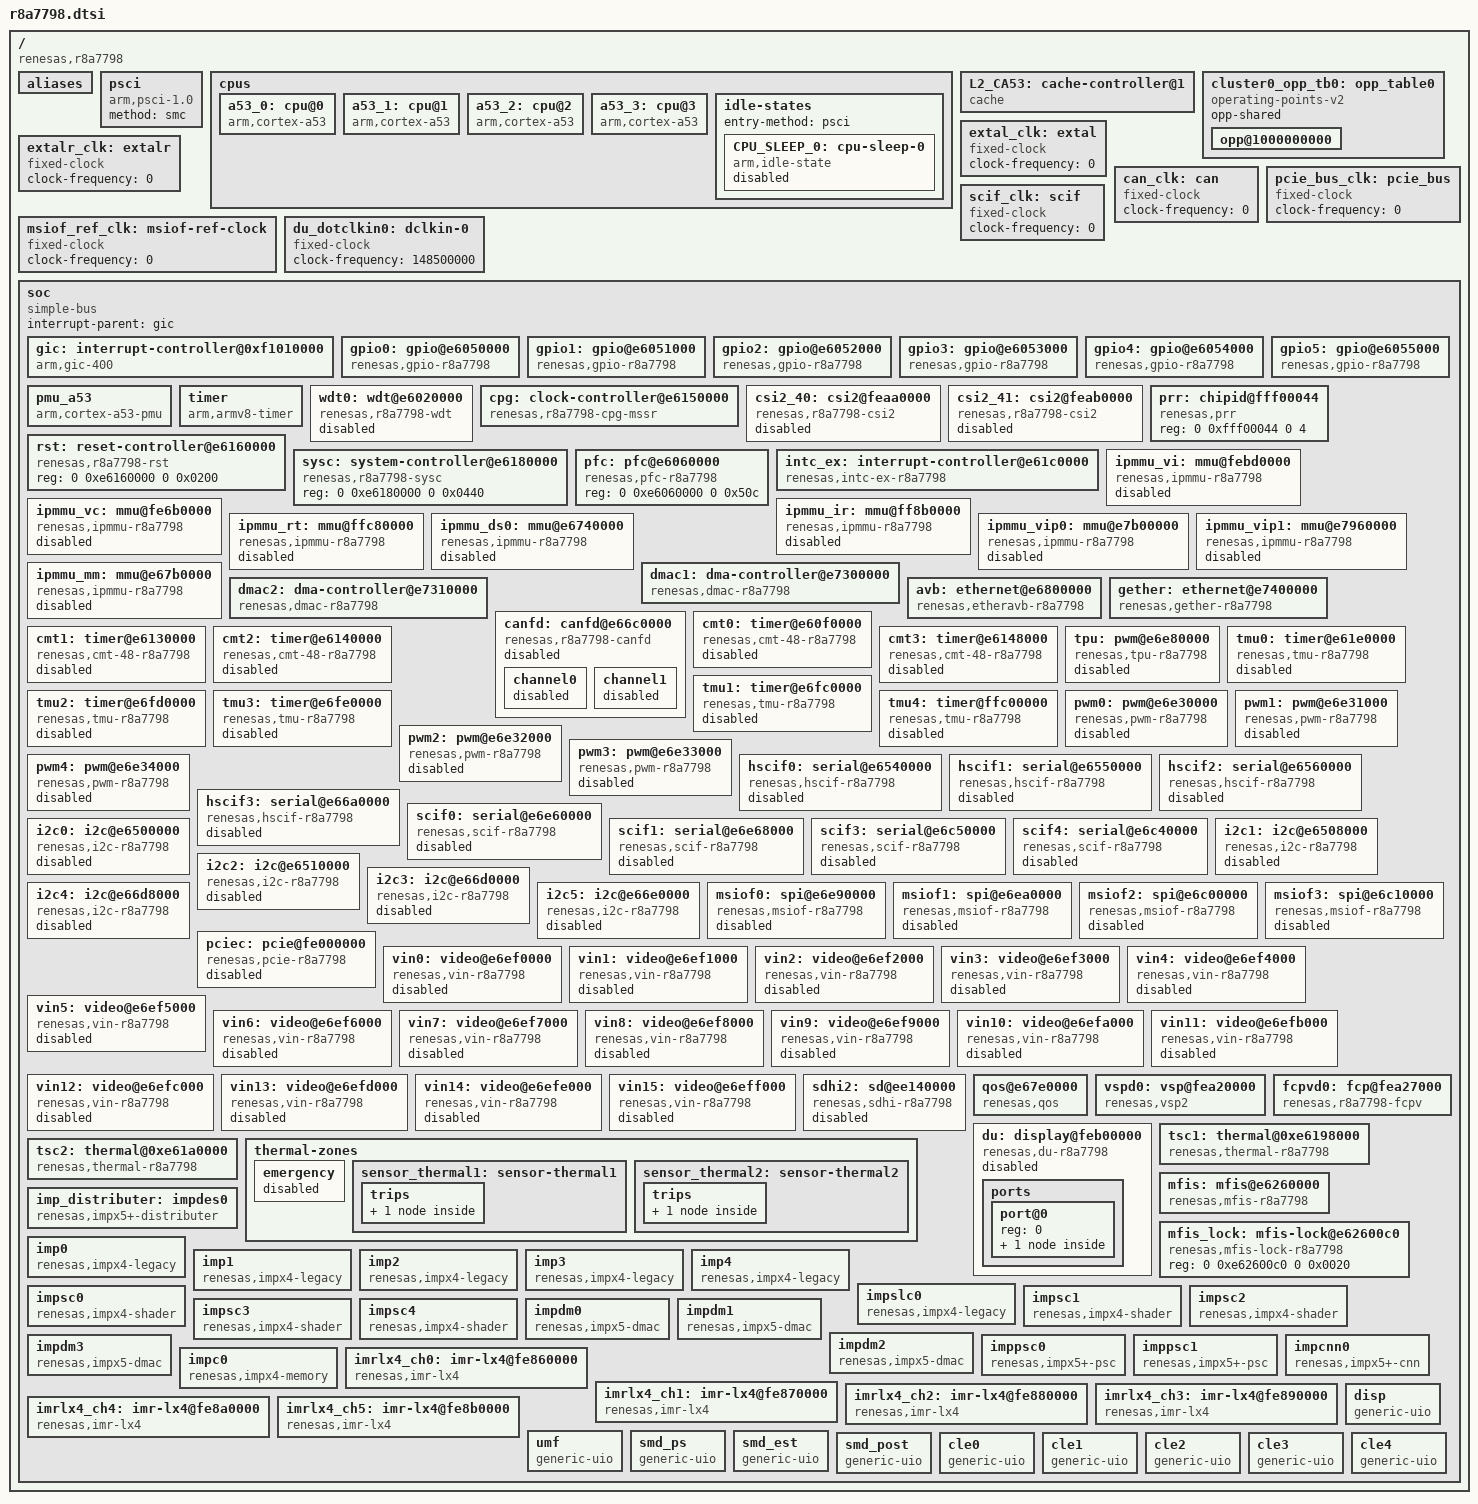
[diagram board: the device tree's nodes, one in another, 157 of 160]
/*
 * Device Tree Source for the r8a7798 SoC
 *
 * Copyright (C) 2018 Renesas Electronics Corp.
 * Copyright (C) 2018 Cogent Embedded, Inc.
 *
 * This file is licensed under the terms of the GNU General Public License
 * version 2.  This program is licensed "as is" without any warranty of any
 * kind, whether express or implied.
 */

#include <dt-bindings/clock/r8a7798-cpg-mssr.h>
#include <dt-bindings/interrupt-controller/arm-gic.h>
#include <dt-bindings/power/r8a7798-sysc.h>

/ {
	compatible = "renesas,r8a7798";
	#address-cells = <2>;
	#size-cells = <2>;

	aliases {
		csi2_40 = &csi2_40;
		csi2_41 = &csi2_41;
		i2c0 = &i2c0;
		i2c1 = &i2c1;
		i2c2 = &i2c2;
		i2c3 = &i2c3;
		i2c4 = &i2c4;
		i2c5 = &i2c5;
		spi1 = &msiof0;
		spi2 = &msiof1;
		spi3 = &msiof2;
		spi4 = &msiof3;
		vin0 = &vin0;
		vin1 = &vin1;
		vin2 = &vin2;
		vin3 = &vin3;
		vin4 = &vin4;
		vin5 = &vin5;
		vin6 = &vin6;
		vin7 = &vin7;
		vin8 = &vin8;
		vin9 = &vin9;
		vin10 = &vin10;
		vin11 = &vin11;
		vin12 = &vin12;
		vin13 = &vin13;
		vin14 = &vin14;
		vin15 = &vin15;
		tsc0 = &tsc1;
		tsc1 = &tsc2;
	};

	psci {
		compatible = "arm,psci-1.0";
		method = "smc";
	};

	cpus {
		#address-cells = <1>;
		#size-cells = <0>;

		a53_0: cpu@0 {
			compatible = "arm,cortex-a53", "arm,armv8";
			reg = <0x0>;
			device_type = "cpu";
			power-domains = <&sysc R8A7798_PD_CA53_CPU0>;
			next-level-cache = <&L2_CA53>;
			enable-method = "psci";
			cpu-idle-states = <&CPU_SLEEP_0>;
			#cooling-cells = <2>;
			dynamic-power-coefficient = <277>;
			cooling-min-level = <0>;
			cooling-max-level = <2>;
			clocks =<&cpg CPG_CORE R8A7798_CLK_Z2>;
			operating-points-v2 = <&cluster0_opp_tb0>;
			/*cpu-supply = <&vdd_dvfs>;*/
		};

		a53_1: cpu@1 {
			compatible = "arm,cortex-a53","arm,armv8";
			reg = <0x1>;
			device_type = "cpu";
			power-domains = <&sysc R8A7798_PD_CA53_CPU1>;
			next-level-cache = <&L2_CA53>;
			enable-method = "psci";
			cpu-idle-states = <&CPU_SLEEP_0>;
			operating-points-v2 = <&cluster0_opp_tb0>;
		};

		a53_2: cpu@2 {
			compatible = "arm,cortex-a53","arm,armv8";
			reg = <0x2>;
			device_type = "cpu";
			power-domains = <&sysc R8A7798_PD_CA53_CPU2>;
			next-level-cache = <&L2_CA53>;
			enable-method = "psci";
			cpu-idle-states = <&CPU_SLEEP_0>;
			operating-points-v2 = <&cluster0_opp_tb0>;
		};

		a53_3: cpu@3 {
			compatible = "arm,cortex-a53","arm,armv8";
			reg = <0x3>;
			device_type = "cpu";
			power-domains = <&sysc R8A7798_PD_CA53_CPU3>;
			next-level-cache = <&L2_CA53>;
			enable-method = "psci";
			cpu-idle-states = <&CPU_SLEEP_0>;
			operating-points-v2 = <&cluster0_opp_tb0>;
		};

		idle-states {
			entry-method = "psci";

			CPU_SLEEP_0: cpu-sleep-0 {
				compatible = "arm,idle-state";
				arm,psci-suspend-param = <0x0010000>;
				local-timer-stop;
				entry-latency-us = <639>;
				exit-latency-us = <680>;
				min-residency-us = <1088>;
				status = "disabled";
			};
		};
	};

	L2_CA53: cache-controller@1 {
		compatible = "cache";
		power-domains = <&sysc R8A7798_PD_CA53_SCU>;
		cache-unified;
		cache-level = <2>;
	};

	cluster0_opp_tb0: opp_table0 {
		compatible = "operating-points-v2";
		opp-shared;

		opp@1000000000 {
			opp-hz = /bits/ 64 <1000000000>;
			opp-microvolt = <850000>; /* TBD; section 87.2 */
			clock-latency-ns = <300000>;
		};
	};

	extal_clk: extal {
		compatible = "fixed-clock";
		#clock-cells = <0>;
		/* This value must be overridden by the board */
		clock-frequency = <0>;
	};

	extalr_clk: extalr {
		compatible = "fixed-clock";
		#clock-cells = <0>;
		/* This value must be overridden by the board */
		clock-frequency = <0>;
	};

	can_clk: can {
		compatible = "fixed-clock";
		#clock-cells = <0>;
		clock-frequency = <0>;
	};

	/* MSIOF reference clock - to be overridden by boards that provide it */
	msiof_ref_clk: msiof-ref-clock {
		compatible = "fixed-clock";
		#clock-cells = <0>;
		clock-frequency = <0>;
	};

	/* External PCIe clock - can be overridden by the board */
	pcie_bus_clk: pcie_bus {
		compatible = "fixed-clock";
		#clock-cells = <0>;
		clock-frequency = <0>;
	};

	/* External SCIF clock - to be overridden by boards that provide it */
	scif_clk: scif {
		compatible = "fixed-clock";
		#clock-cells = <0>;
		clock-frequency = <0>;
	};

	/* DU input dot clock - tob be overriden by boards that provide it */
	du_dotclkin0: dclkin-0 {
		compatible = "fixed-clock";
		#clock-cells = <0>;
		clock-frequency = <148500000>;
	};

	soc {
		compatible = "simple-bus";
		interrupt-parent = <&gic>;

		#address-cells = <2>;
		#size-cells = <2>;
		ranges;

		gic: interrupt-controller@0xf1010000 {
			compatible = "arm,gic-400";
			#interrupt-cells = <3>;
			#address-cells = <0>;
			interrupt-controller;
			reg = <0x0 0xf1010000 0 0x1000>,
			      <0x0 0xf1020000 0 0x20000>,
			      <0x0 0xf1040000 0 0x20000>,
			      <0x0 0xf1060000 0 0x20000>;
			interrupts = <GIC_PPI 9
					(GIC_CPU_MASK_SIMPLE(8) | IRQ_TYPE_LEVEL_HIGH)>;
		};

		gpio0: gpio@e6050000 {
			compatible = "renesas,gpio-r8a7798",
				     "renesas,gpio-rcar";
			reg = <0 0xe6050000 0 0x50>;
			interrupts = <GIC_SPI 4 IRQ_TYPE_LEVEL_HIGH>;
			#gpio-cells = <2>;
			gpio-controller;
			gpio-ranges = <&pfc 0 0 22>;
			#interrupt-cells = <2>;
			interrupt-controller;
			clocks = <&cpg CPG_MOD 912>;
			power-domains = <&sysc R8A7798_PD_ALWAYS_ON>;
		};

		gpio1: gpio@e6051000 {
			compatible = "renesas,gpio-r8a7798",
				     "renesas,gpio-rcar";
			reg = <0 0xe6051000 0 0x50>;
			interrupts = <GIC_SPI 5 IRQ_TYPE_LEVEL_HIGH>;
			#gpio-cells = <2>;
			gpio-controller;
			gpio-ranges = <&pfc 0 32 28>;
			#interrupt-cells = <2>;
			interrupt-controller;
			clocks = <&cpg CPG_MOD 911>;
			power-domains = <&sysc R8A7798_PD_ALWAYS_ON>;
		};

		gpio2: gpio@e6052000 {
			compatible = "renesas,gpio-r8a7798",
				     "renesas,gpio-rcar";
			reg = <0 0xe6052000 0 0x50>;
			interrupts = <GIC_SPI 6 IRQ_TYPE_LEVEL_HIGH>;
			#gpio-cells = <2>;
			gpio-controller;
			gpio-ranges = <&pfc 0 64 29>;
			#interrupt-cells = <2>;
			interrupt-controller;
			clocks = <&cpg CPG_MOD 910>;
			power-domains = <&sysc R8A7798_PD_ALWAYS_ON>;
		};

		gpio3: gpio@e6053000 {
			compatible = "renesas,gpio-r8a7798",
				     "renesas,gpio-rcar";
			reg = <0 0xe6053000 0 0x50>;
			interrupts = <GIC_SPI 7 IRQ_TYPE_LEVEL_HIGH>;
			#gpio-cells = <2>;
			gpio-controller;
			gpio-ranges = <&pfc 0 96 17>;
			#interrupt-cells = <2>;
			interrupt-controller;
			clocks = <&cpg CPG_MOD 909>;
			power-domains = <&sysc R8A7798_PD_ALWAYS_ON>;
		};

		gpio4: gpio@e6054000 {
			compatible = "renesas,gpio-r8a7798",
				     "renesas,gpio-rcar";
			reg = <0 0xe6054000 0 0x50>;
			interrupts = <GIC_SPI 8 IRQ_TYPE_LEVEL_HIGH>;
			#gpio-cells = <2>;
			gpio-controller;
			gpio-ranges = <&pfc 0 128 25>;
			#interrupt-cells = <2>;
			interrupt-controller;
			clocks = <&cpg CPG_MOD 908>;
			power-domains = <&sysc R8A7798_PD_ALWAYS_ON>;
		};

		gpio5: gpio@e6055000 {
			compatible = "renesas,gpio-r8a7798",
				     "renesas,gpio-rcar";
			reg = <0 0xe6055000 0 0x50>;
			interrupts = <GIC_SPI 9 IRQ_TYPE_LEVEL_HIGH>;
			#gpio-cells = <2>;
			gpio-controller;
			gpio-ranges = <&pfc 0 160 15>;
			#interrupt-cells = <2>;
			interrupt-controller;
			clocks = <&cpg CPG_MOD 907>;
			power-domains = <&sysc R8A7798_PD_ALWAYS_ON>;
		};

		pmu_a53 {
			compatible = "arm,cortex-a53-pmu";
			interrupts = <GIC_SPI 84 IRQ_TYPE_LEVEL_HIGH>,
				     <GIC_SPI 85 IRQ_TYPE_LEVEL_HIGH>,
				     <GIC_SPI 86 IRQ_TYPE_LEVEL_HIGH>,
				     <GIC_SPI 87 IRQ_TYPE_LEVEL_HIGH>;
			interrupt-affinity = <&a53_0>,
					     <&a53_1>,
					     <&a53_2>,
					     <&a53_3>;
		};

		timer {
			compatible = "arm,armv8-timer";
			interrupts = <GIC_PPI 13
					(GIC_CPU_MASK_SIMPLE(8) | IRQ_TYPE_LEVEL_LOW)>,
				     <GIC_PPI 14
					(GIC_CPU_MASK_SIMPLE(8) | IRQ_TYPE_LEVEL_LOW)>,
				     <GIC_PPI 11
					(GIC_CPU_MASK_SIMPLE(8) | IRQ_TYPE_LEVEL_LOW)>,
				     <GIC_PPI 10
					(GIC_CPU_MASK_SIMPLE(8) | IRQ_TYPE_LEVEL_LOW)>;
		};

		wdt0: wdt@e6020000 {
			compatible = "renesas,r8a7798-wdt", "renesas,rcar-gen3-wdt";
			reg = <0 0xe6020000 0 0x0c>;
			clocks = <&cpg CPG_MOD 402>;
			power-domains = <&sysc R8A7798_PD_ALWAYS_ON>;
			status = "disabled";
		};

		cpg: clock-controller@e6150000 {
			compatible = "renesas,r8a7798-cpg-mssr";
			reg = <0 0xe6150000 0 0x1000>;
			clocks = <&extal_clk>, <&extalr_clk>;
			clock-names = "extal", "extalr";
			#clock-cells = <2>;
			#power-domain-cells = <0>;
		};

		csi2_40: csi2@feaa0000 {
			compatible = "renesas,r8a7798-csi2";
			reg = <0 0xfeaa0000 0 0x10000>;
			interrupts = <GIC_SPI 246 IRQ_TYPE_LEVEL_HIGH>;
			clocks = <&cpg CPG_MOD 716>;
			power-domains = <&sysc R8A7798_PD_ALWAYS_ON>;
			status = "disabled";
		};

		csi2_41: csi2@feab0000 {
			compatible = "renesas,r8a7798-csi2";
			reg = <0 0xfeab0000 0 0x10000>;
			interrupts = <GIC_SPI 247 IRQ_TYPE_LEVEL_HIGH>;
			clocks = <&cpg CPG_MOD 715>;
			power-domains = <&sysc R8A7798_PD_ALWAYS_ON>;
			status = "disabled";
		};

		prr: chipid@fff00044 {
			compatible = "renesas,prr";
			reg = <0 0xfff00044 0 4>;
		};

		rst: reset-controller@e6160000 {
			compatible = "renesas,r8a7798-rst";
			reg = <0 0xe6160000 0 0x0200>;
		};

		sysc: system-controller@e6180000 {
			compatible = "renesas,r8a7798-sysc";
			reg = <0 0xe6180000 0 0x0440>;
			#power-domain-cells = <1>;
		};

		pfc: pfc@e6060000 {
			compatible = "renesas,pfc-r8a7798";
			reg = <0 0xe6060000 0 0x50c>;
		};

		intc_ex: interrupt-controller@e61c0000 {
			compatible = "renesas,intc-ex-r8a7798", "renesas,irqc";
			#interrupt-cells = <2>;
			interrupt-controller;
			reg = <0 0xe61c0000 0 0x200>;
			interrupts = <GIC_SPI 0 IRQ_TYPE_LEVEL_HIGH
				      GIC_SPI 1 IRQ_TYPE_LEVEL_HIGH
				      GIC_SPI 2 IRQ_TYPE_LEVEL_HIGH
				      GIC_SPI 3 IRQ_TYPE_LEVEL_HIGH
				      GIC_SPI 18 IRQ_TYPE_LEVEL_HIGH
				      GIC_SPI 161 IRQ_TYPE_LEVEL_HIGH>;		/* SPI1:IRQ1, SPI2:IRQ2, SPI3:IRQ3, SPI18:IRQ4, SPI161:IRQ5 */
			clocks = <&cpg CPG_MOD 407>;				/* RMSTPCR4/bit7:INTC-EX */
			power-domains = <&sysc R8A7798_PD_ALWAYS_ON>;
		};

		ipmmu_vi: mmu@febd0000 {
			compatible = "renesas,ipmmu-r8a7798";
			reg = <0 0xfebd0000 0 0x1000>; /* IPMMU-VI */
			renesas,ipmmu-main = <&ipmmu_mm 14>;
			#iommu-cells = <1>;
			status = "disabled";
		};

		ipmmu_vc: mmu@fe6b0000 {
			compatible = "renesas,ipmmu-r8a7798";
			reg = <0 0xfe6b0000 0 0x1000>; /* IPMMU-VC */
			renesas,ipmmu-main = <&ipmmu_mm 12>;
			#iommu-cells = <1>;
			status = "disabled";
		};

		ipmmu_ir: mmu@ff8b0000 {
			compatible = "renesas,ipmmu-r8a7798";
			reg = <0 0xff8b0000 0 0x1000>; /* IPMMU-IR */
			renesas,ipmmu-main = <&ipmmu_mm 3>;
			#iommu-cells = <1>;
			status = "disabled";
		};

		ipmmu_rt: mmu@ffc80000 {
			compatible = "renesas,ipmmu-r8a7798";
			reg = <0 0xffc80000 0 0x1000>; /* IPMMU-RT */
			renesas,ipmmu-main = <&ipmmu_mm 10>;
			#iommu-cells = <1>;
			status = "disabled";
		};

		ipmmu_ds0: mmu@e6740000 {
			compatible = "renesas,ipmmu-r8a7798";
			reg = <0 0xe6740000 0 0x1000>; /* IPMMU-DS1 */
			renesas,ipmmu-main = <&ipmmu_mm 0>;
			#iommu-cells = <1>;
			status = "disabled";
		};

		ipmmu_vip0: mmu@e7b00000 {
			compatible = "renesas,ipmmu-r8a7798";
			reg = <0 0xe7b00000 0 0x1000>; /* IPMMU-VIP0 */
			renesas,ipmmu-main = <&ipmmu_mm 0>; /* FIXME missing in datasheet */
			#iommu-cells = <1>;
			status = "disabled";
		};

		ipmmu_vip1: mmu@e7960000 {
			compatible = "renesas,ipmmu-r8a7798";
			reg = <0 0xe7960000 0 0x1000>; /* IPMMU-VIP1 */
			renesas,ipmmu-main = <&ipmmu_mm 0>; /* FIXME missing in datasheet */
			#iommu-cells = <1>;
			status = "disabled";
		};

		ipmmu_mm: mmu@e67b0000 {
			compatible = "renesas,ipmmu-r8a7798";
			reg = <0 0xe67b0000 0 0x1000>; /* IPMMU-MM */
			interrupts = <GIC_SPI 196 IRQ_TYPE_LEVEL_HIGH>,
				     <GIC_SPI 197 IRQ_TYPE_LEVEL_HIGH>;
			#iommu-cells = <1>;
			status = "disabled";
		};

		dmac1: dma-controller@e7300000 {
			compatible = "renesas,dmac-r8a7798",
				     "renesas,rcar-dmac";
			reg = <0 0xe7300000 0 0x10000>;
			interrupts = <GIC_SPI 220 IRQ_TYPE_LEVEL_HIGH
				      GIC_SPI 216 IRQ_TYPE_LEVEL_HIGH
				      GIC_SPI 217 IRQ_TYPE_LEVEL_HIGH
				      GIC_SPI 218 IRQ_TYPE_LEVEL_HIGH
				      GIC_SPI 219 IRQ_TYPE_LEVEL_HIGH
				      GIC_SPI 308 IRQ_TYPE_LEVEL_HIGH
				      GIC_SPI 309 IRQ_TYPE_LEVEL_HIGH
				      GIC_SPI 310 IRQ_TYPE_LEVEL_HIGH
				      GIC_SPI 311 IRQ_TYPE_LEVEL_HIGH
				      GIC_SPI 353 IRQ_TYPE_LEVEL_HIGH
				      GIC_SPI 354 IRQ_TYPE_LEVEL_HIGH
				      GIC_SPI 355 IRQ_TYPE_LEVEL_HIGH
				      GIC_SPI 356 IRQ_TYPE_LEVEL_HIGH
				      GIC_SPI 357 IRQ_TYPE_LEVEL_HIGH
				      GIC_SPI 358 IRQ_TYPE_LEVEL_HIGH
				      GIC_SPI 359 IRQ_TYPE_LEVEL_HIGH
				      GIC_SPI 360 IRQ_TYPE_LEVEL_HIGH>;

			interrupt-names = "error",
					"ch0", "ch1", "ch2", "ch3",
					"ch4", "ch5", "ch6", "ch7",
					"ch8", "ch9", "ch10", "ch11",
					"ch12", "ch13", "ch14", "ch15";
			clocks = <&cpg CPG_MOD 218>;
			clock-names = "fck";
			power-domains = <&sysc R8A7798_PD_ALWAYS_ON>;
			#dma-cells = <1>;
			dma-channels = <16>;
			iommus = <&ipmmu_ds0 0>, <&ipmmu_ds0 1>,
			       <&ipmmu_ds0 2>, <&ipmmu_ds0 3>,
			       <&ipmmu_ds0 4>, <&ipmmu_ds0 5>,
			       <&ipmmu_ds0 6>, <&ipmmu_ds0 7>,
			       <&ipmmu_ds0 8>, <&ipmmu_ds0 9>,
			       <&ipmmu_ds0 10>, <&ipmmu_ds0 11>,
			       <&ipmmu_ds0 12>, <&ipmmu_ds0 13>,
			       <&ipmmu_ds0 14>, <&ipmmu_ds0 15>;
		};

		dmac2: dma-controller@e7310000 {
			compatible = "renesas,dmac-r8a7798",
				     "renesas,rcar-dmac";
			reg = <0 0xe7310000 0 0x10000>;
			interrupts = <GIC_SPI 307 IRQ_TYPE_LEVEL_HIGH
				      GIC_SPI 312 IRQ_TYPE_LEVEL_HIGH
				      GIC_SPI 313 IRQ_TYPE_LEVEL_HIGH
				      GIC_SPI 314 IRQ_TYPE_LEVEL_HIGH
				      GIC_SPI 315 IRQ_TYPE_LEVEL_HIGH
				      GIC_SPI 316 IRQ_TYPE_LEVEL_HIGH
				      GIC_SPI 317 IRQ_TYPE_LEVEL_HIGH
				      GIC_SPI 318 IRQ_TYPE_LEVEL_HIGH
				      GIC_SPI 319 IRQ_TYPE_LEVEL_HIGH
				      GIC_SPI 361 IRQ_TYPE_LEVEL_HIGH
				      GIC_SPI 362 IRQ_TYPE_LEVEL_HIGH
				      GIC_SPI 363 IRQ_TYPE_LEVEL_HIGH
				      GIC_SPI 364 IRQ_TYPE_LEVEL_HIGH
				      GIC_SPI 365 IRQ_TYPE_LEVEL_HIGH
				      GIC_SPI 366 IRQ_TYPE_LEVEL_HIGH
				      GIC_SPI 367 IRQ_TYPE_LEVEL_HIGH
				      GIC_SPI 368 IRQ_TYPE_LEVEL_HIGH>;		/* SPI307::SYS-DMAC2 err,
										   SPI312~319:SYS-DMAC2.ch0~SYS-DMAC1.ch7 */
			interrupt-names = "error",
					"ch0", "ch1", "ch2", "ch3",
					"ch4", "ch5", "ch6", "ch7",
					"ch8", "ch9", "ch10", "ch11",
					"ch12", "ch13", "ch14", "ch15";
			clocks = <&cpg CPG_MOD 217>;				/* RMSTPCR2/bit17:SYS-DMAC2 */
			clock-names = "fck";
			power-domains = <&sysc R8A7798_PD_ALWAYS_ON>;
			#dma-cells = <1>;
			dma-channels = <16>;
			iommus = <&ipmmu_ds0 16>, <&ipmmu_ds0 17>,
			       <&ipmmu_ds0 18>, <&ipmmu_ds0 19>,
			       <&ipmmu_ds0 20>, <&ipmmu_ds0 21>,
			       <&ipmmu_ds0 22>, <&ipmmu_ds0 23>,
			       <&ipmmu_ds0 24>, <&ipmmu_ds0 25>,
			       <&ipmmu_ds0 26>, <&ipmmu_ds0 27>,
			       <&ipmmu_ds0 28>, <&ipmmu_ds0 29>,
			       <&ipmmu_ds0 30>, <&ipmmu_ds0 31>;
		};

		avb: ethernet@e6800000 {
			compatible = "renesas,etheravb-r8a7798",
				     "renesas,etheravb-rcar-gen3";
			reg = <0 0xe6800000 0 0x800>, <0 0xe6a00000 0 0x10000>;
			interrupts = <GIC_SPI 39 IRQ_TYPE_LEVEL_HIGH>,
				     <GIC_SPI 40 IRQ_TYPE_LEVEL_HIGH>,
				     <GIC_SPI 41 IRQ_TYPE_LEVEL_HIGH>,
				     <GIC_SPI 42 IRQ_TYPE_LEVEL_HIGH>,
				     <GIC_SPI 43 IRQ_TYPE_LEVEL_HIGH>,
				     <GIC_SPI 44 IRQ_TYPE_LEVEL_HIGH>,
				     <GIC_SPI 45 IRQ_TYPE_LEVEL_HIGH>,
				     <GIC_SPI 46 IRQ_TYPE_LEVEL_HIGH>,
				     <GIC_SPI 47 IRQ_TYPE_LEVEL_HIGH>,
				     <GIC_SPI 48 IRQ_TYPE_LEVEL_HIGH>,
				     <GIC_SPI 49 IRQ_TYPE_LEVEL_HIGH>,
				     <GIC_SPI 50 IRQ_TYPE_LEVEL_HIGH>,
				     <GIC_SPI 51 IRQ_TYPE_LEVEL_HIGH>,
				     <GIC_SPI 52 IRQ_TYPE_LEVEL_HIGH>,
				     <GIC_SPI 53 IRQ_TYPE_LEVEL_HIGH>,
				     <GIC_SPI 54 IRQ_TYPE_LEVEL_HIGH>,
				     <GIC_SPI 55 IRQ_TYPE_LEVEL_HIGH>,
				     <GIC_SPI 56 IRQ_TYPE_LEVEL_HIGH>,
				     <GIC_SPI 57 IRQ_TYPE_LEVEL_HIGH>,
				     <GIC_SPI 58 IRQ_TYPE_LEVEL_HIGH>,
				     <GIC_SPI 59 IRQ_TYPE_LEVEL_HIGH>,
				     <GIC_SPI 60 IRQ_TYPE_LEVEL_HIGH>,
				     <GIC_SPI 61 IRQ_TYPE_LEVEL_HIGH>,
				     <GIC_SPI 62 IRQ_TYPE_LEVEL_HIGH>,
				     <GIC_SPI 63 IRQ_TYPE_LEVEL_HIGH>;		/* SPI39~63:Ethernet AVB.ch0~24 */
										/* @@ errreq_avb_p[0]~[3] add (T.B.D) */
			interrupt-names = "ch0", "ch1", "ch2", "ch3",
					  "ch4", "ch5", "ch6", "ch7",
					  "ch8", "ch9", "ch10", "ch11",
					  "ch12", "ch13", "ch14", "ch15",
					  "ch16", "ch17", "ch18", "ch19",
					  "ch20", "ch21", "ch22", "ch23",
					  "ch24";
			clocks = <&cpg CPG_MOD 812>;				/* RMSTPCR8/bit12:EAVB-IF */
			power-domains = <&sysc R8A7798_PD_ALWAYS_ON>;
			phy-mode = "rgmii-id";
			#address-cells = <1>;
			#size-cells = <0>;
		};

		gether: ethernet@e7400000 {
			compatible = "renesas,gether-r8a7798";
			reg = <0 0xe7400000 0 0x1000>;
			interrupts = <GIC_SPI 21 IRQ_TYPE_LEVEL_HIGH>;
			clocks = <&cpg CPG_MOD 813>;
			power-domains = <&sysc R8A7798_PD_ALWAYS_ON>;
			phy-mode = "rgmii";
			#address-cells = <1>;
			#size-cells = <0>;
		};

		canfd: canfd@e66c0000 {
			compatible = "renesas,r8a7798-canfd",
				     "renesas,rcar-gen3-canfd";
			reg = <0 0xe66c0000 0 0x8000>;
			interrupts = <GIC_SPI 29 IRQ_TYPE_LEVEL_HIGH>,
				   <GIC_SPI 30 IRQ_TYPE_LEVEL_HIGH>;
			clocks = <&cpg CPG_MOD 914>,
			       <&cpg CPG_CORE R8A7798_CLK_CANFD>,
			       <&can_clk>;
			clock-names = "fck", "canfd", "can_clk";
			assigned-clocks = <&cpg CPG_CORE R8A7798_CLK_CANFD>;
			assigned-clock-rates = <40000000>;
			power-domains = <&sysc R8A7798_PD_ALWAYS_ON>;
			status = "disabled";

			channel0 {
				status = "disabled";
			};

			channel1 {
				status = "disabled";
			};
		};


		cmt0: timer@e60f0000 {
			compatible = "renesas,cmt-48-r8a7798", "renesas,cmt-48-gen2";
			reg = <0 0xe60f0000 0 0x1004>;
			interrupts = <GIC_SPI 142 IRQ_TYPE_LEVEL_HIGH>,
				     <GIC_SPI 143 IRQ_TYPE_LEVEL_HIGH>;
			clocks = <&cpg CPG_MOD 303>;
			clock-names = "fck";
			power-domains = <&sysc R8A7798_PD_ALWAYS_ON>;

			renesas,channels-mask = <0x60>;

			status = "disabled";
		};

		cmt1: timer@e6130000 {
			compatible = "renesas,cmt-48-r8a7798", "renesas,cmt-48-gen2";
			reg = <0 0xe6130000 0 0x1004>;
			interrupts = <GIC_SPI 120 IRQ_TYPE_LEVEL_HIGH>,
				     <GIC_SPI 121 IRQ_TYPE_LEVEL_HIGH>,
				     <GIC_SPI 122 IRQ_TYPE_LEVEL_HIGH>,
				     <GIC_SPI 123 IRQ_TYPE_LEVEL_HIGH>,
				     <GIC_SPI 124 IRQ_TYPE_LEVEL_HIGH>,
				     <GIC_SPI 125 IRQ_TYPE_LEVEL_HIGH>,
				     <GIC_SPI 126 IRQ_TYPE_LEVEL_HIGH>,
				     <GIC_SPI 127 IRQ_TYPE_LEVEL_HIGH>;
			clocks = <&cpg CPG_MOD 302>;
			clock-names = "fck";
			power-domains = <&sysc R8A7798_PD_ALWAYS_ON>;

			renesas,channels-mask = <0xff>;

			status = "disabled";
		};

		cmt2: timer@e6140000 {
			compatible = "renesas,cmt-48-r8a7798", "renesas,cmt-48-gen2";
			reg = <0 0xe6140000 0 0x1004>;
			interrupts = <GIC_SPI 258 IRQ_TYPE_LEVEL_HIGH>,
				     <GIC_SPI 259 IRQ_TYPE_LEVEL_HIGH>,
				     <GIC_SPI 260 IRQ_TYPE_LEVEL_HIGH>,
				     <GIC_SPI 261 IRQ_TYPE_LEVEL_HIGH>,
				     <GIC_SPI 262 IRQ_TYPE_LEVEL_HIGH>,
				     <GIC_SPI 263 IRQ_TYPE_LEVEL_HIGH>,
				     <GIC_SPI 264 IRQ_TYPE_LEVEL_HIGH>,
				     <GIC_SPI 265 IRQ_TYPE_LEVEL_HIGH>;
			clocks = <&cpg CPG_MOD 301>;
			clock-names = "fck";
			power-domains = <&sysc R8A7798_PD_ALWAYS_ON>;

			renesas,channels-mask = <0xff>;

			status = "disabled";
		};

		cmt3: timer@e6148000 {
			compatible = "renesas,cmt-48-r8a7798", "renesas,cmt-48-gen2";
			reg = <0 0xe6148000 0 0x1004>;
			interrupts = <GIC_SPI 273 IRQ_TYPE_LEVEL_HIGH>,
				     <GIC_SPI 274 IRQ_TYPE_LEVEL_HIGH>,
				     <GIC_SPI 275 IRQ_TYPE_LEVEL_HIGH>,
				     <GIC_SPI 276 IRQ_TYPE_LEVEL_HIGH>,
				     <GIC_SPI 277 IRQ_TYPE_LEVEL_HIGH>,
				     <GIC_SPI 278 IRQ_TYPE_LEVEL_HIGH>,
				     <GIC_SPI 279 IRQ_TYPE_LEVEL_HIGH>,
				     <GIC_SPI 280 IRQ_TYPE_LEVEL_HIGH>;
			clocks = <&cpg CPG_MOD 300>;
			clock-names = "fck";
			power-domains = <&sysc R8A7798_PD_ALWAYS_ON>;

			renesas,channels-mask = <0xff>;

			status = "disabled";
		};

		tpu: pwm@e6e80000 {
			compatible = "renesas,tpu-r8a7798", "renesas,tpu";
			reg = <0 0xe6e80000 0 0x100>;
			clocks = <&cpg CPG_MOD 304>;
			power-domains = <&sysc R8A7798_PD_ALWAYS_ON>;
			status = "disabled";
			#pwm-cells = <4>;
		};

		tmu0: timer@e61e0000 {
			compatible = "renesas,tmu-r8a7798", "renesas,tmu";
			reg = <0 0xe61e0000 0 0x30>;
			interrupts = <GIC_SPI 136 IRQ_TYPE_LEVEL_HIGH>,
				     <GIC_SPI 137 IRQ_TYPE_LEVEL_HIGH>,
				     <GIC_SPI 138 IRQ_TYPE_LEVEL_HIGH>;
			clocks = <&cpg CPG_MOD 125>;
			clock-names = "fck";
			power-domains = <&sysc R8A7798_PD_ALWAYS_ON>;
			#renesas,channels = <3>;
			status = "disabled";
		};

		tmu1: timer@e6fc0000 {
			compatible = "renesas,tmu-r8a7798", "renesas,tmu";
			reg = <0 0xe6fc0000 0 0x30>;
			interrupts = <GIC_SPI 128 IRQ_TYPE_LEVEL_HIGH>,
				     <GIC_SPI 129 IRQ_TYPE_LEVEL_HIGH>,
				     <GIC_SPI 130 IRQ_TYPE_LEVEL_HIGH>,
				     <GIC_SPI 147 IRQ_TYPE_LEVEL_HIGH>;
			clocks = <&cpg CPG_MOD 124>;
			clock-names = "fck";
			power-domains = <&sysc R8A7798_PD_ALWAYS_ON>;
			#renesas,channels = <3>;
			status = "disabled";
		};

		tmu2: timer@e6fd0000 {
			compatible = "renesas,tmu-r8a7798", "renesas,tmu";
			reg = <0 0xe6fd0000 0 0x30>;
			interrupts = <GIC_SPI 303 IRQ_TYPE_LEVEL_HIGH>,
				     <GIC_SPI 304 IRQ_TYPE_LEVEL_HIGH>,
				     <GIC_SPI 305 IRQ_TYPE_LEVEL_HIGH>,
				     <GIC_SPI 306 IRQ_TYPE_LEVEL_HIGH>;
			clocks = <&cpg CPG_MOD 123>;
			clock-names = "fck";
			power-domains = <&sysc R8A7798_PD_ALWAYS_ON>;
			#renesas,channels = <3>;
			status = "disabled";
		};

		tmu3: timer@e6fe0000 {
			compatible = "renesas,tmu-r8a7798", "renesas,tmu";
			reg = <0 0xe6fe0000 0 0x30>;
			interrupts = <GIC_SPI 131 IRQ_TYPE_LEVEL_HIGH>,
				     <GIC_SPI 132 IRQ_TYPE_LEVEL_HIGH>,
				     <GIC_SPI 133 IRQ_TYPE_LEVEL_HIGH>,
				     <GIC_SPI 146 IRQ_TYPE_LEVEL_HIGH>;
			clocks = <&cpg CPG_MOD 122>;
			clock-names = "fck";
			power-domains = <&sysc R8A7798_PD_ALWAYS_ON>;
			#renesas,channels = <3>;
			status = "disabled";
		};

		tmu4: timer@ffc00000 {
			compatible = "renesas,tmu-r8a7798", "renesas,tmu";
			reg = <0 0xffc00000 0 0x30>;
			interrupts = <GIC_SPI 116 IRQ_TYPE_LEVEL_HIGH>,
				     <GIC_SPI 117 IRQ_TYPE_LEVEL_HIGH>,
				     <GIC_SPI 118 IRQ_TYPE_LEVEL_HIGH>,
				     <GIC_SPI 369 IRQ_TYPE_LEVEL_HIGH>;
			clocks = <&cpg CPG_MOD 121>;
			clock-names = "fck";
			power-domains = <&sysc R8A7798_PD_ALWAYS_ON>;
			#renesas,channels = <3>;
			status = "disabled";
		};

		pwm0: pwm@e6e30000 {
			compatible = "renesas,pwm-r8a7798", "renesas,pwm-rcar";
			reg = <0 0xe6e30000 0 0x10>;
			#pwm-cells = <2>;
			clocks = <&cpg CPG_MOD 523>;				/* RMSTPCR5/bit23:PWM */
			power-domains = <&sysc R8A7798_PD_ALWAYS_ON>;
			status = "disabled";
		};

		pwm1: pwm@e6e31000 {
			compatible = "renesas,pwm-r8a7798", "renesas,pwm-rcar";
			reg = <0 0xe6e31000 0 0x10>;
			#pwm-cells = <2>;
			clocks = <&cpg CPG_MOD 523>;				/* RMSTPCR5/bit23:PWM */
			power-domains = <&sysc R8A7798_PD_ALWAYS_ON>;
			status = "disabled";
		};

		pwm2: pwm@e6e32000 {
			compatible = "renesas,pwm-r8a7798", "renesas,pwm-rcar";
			reg = <0 0xe6e32000 0 0x10>;
			#pwm-cells = <2>;
			clocks = <&cpg CPG_MOD 523>;				/* RMSTPCR5/bit23:PWM */
			power-domains = <&sysc R8A7798_PD_ALWAYS_ON>;
			status = "disabled";
		};

		pwm3: pwm@e6e33000 {
			compatible = "renesas,pwm-r8a7798", "renesas,pwm-rcar";
			reg = <0 0xe6e33000 0 0x10>;
			#pwm-cells = <2>;
			clocks = <&cpg CPG_MOD 523>;				/* RMSTPCR5/bit23:PWM */
			power-domains = <&sysc R8A7798_PD_ALWAYS_ON>;
			status = "disabled";
		};

		pwm4: pwm@e6e34000 {
			compatible = "renesas,pwm-r8a7798", "renesas,pwm-rcar";
			reg = <0 0xe6e34000 0 0x10>;
			#pwm-cells = <2>;
			clocks = <&cpg CPG_MOD 523>;				/* RMSTPCR5/bit23:PWM */
			power-domains = <&sysc R8A7798_PD_ALWAYS_ON>;
			status = "disabled";
		};

		hscif0: serial@e6540000 {
			compatible = "renesas,hscif-r8a7798",
				     "renesas,rcar-gen3-hscif",
				     "renesas,hscif";
			reg = <0 0xe6540000 0 96>;
			interrupts = <GIC_SPI 154 IRQ_TYPE_LEVEL_HIGH>;		/* SPI154:HSCIF.ch0 */
			clocks = <&cpg CPG_MOD 520>,
				 <&cpg CPG_CORE R8A7798_CLK_S2D1>,
				 <&scif_clk>;					/* RMSTPCR5/bit20:HSCIF0 */
			clock-names = "fck", "brg_int", "scif_clk";
			dmas = <&dmac1 0x31>, <&dmac1 0x30>;
			dma-names = "tx", "rx";
			power-domains = <&sysc R8A7798_PD_ALWAYS_ON>;
			status = "disabled";
		};

		hscif1: serial@e6550000 {
			compatible = "renesas,hscif-r8a7798",
				     "renesas,rcar-gen3-hscif",
				     "renesas,hscif";
			reg = <0 0xe6550000 0 96>;
			interrupts = <GIC_SPI 155 IRQ_TYPE_LEVEL_HIGH>;		/* SPI155:HSCIF.ch1 */
			clocks = <&cpg CPG_MOD 519>,
				 <&cpg CPG_CORE R8A7798_CLK_S2D1>,
				 <&scif_clk>;					/* RMSTPCR5/bit19:HSCIF1 */
			clock-names = "fck", "brg_int", "scif_clk";
			dmas = <&dmac1 0x33>, <&dmac1 0x32>;
			dma-names = "tx", "rx";
			power-domains = <&sysc R8A7798_PD_ALWAYS_ON>;
			status = "disabled";
		};

		hscif2: serial@e6560000 {
			compatible = "renesas,hscif-r8a7798",
				     "renesas,rcar-gen3-hscif",
				     "renesas,hscif";
			reg = <0 0xe6560000 0 96>;
			interrupts = <GIC_SPI 144 IRQ_TYPE_LEVEL_HIGH>;		/* SPI144:HSCIF.ch2 */
			clocks = <&cpg CPG_MOD 518>,
				 <&cpg CPG_CORE R8A7798_CLK_S2D1>,
				 <&scif_clk>;					/* RMSTPCR5/bit18:HSCIF2 */
			clock-names = "fck", "brg_int", "scif_clk";
			dmas = <&dmac1 0x35>, <&dmac1 0x34>;
			dma-names = "tx", "rx";
			power-domains = <&sysc R8A7798_PD_ALWAYS_ON>;
			status = "disabled";
		};

		hscif3: serial@e66a0000 {
			compatible = "renesas,hscif-r8a7798",
				     "renesas,rcar-gen3-hscif",
				     "renesas,hscif";
			reg = <0 0xe66a0000 0 96>;
			//interrupts = <GIC_SPI 145 IRQ_TYPE_LEVEL_HIGH>;		/* SPI145:HSCIF.ch3 */
			clocks = <&cpg CPG_MOD 517>,
				 <&cpg CPG_CORE R8A7798_CLK_S2D1>,
				 <&scif_clk>;					/* RMSTPCR5/bit17:HSCIF3 */
			clock-names = "fck", "brg_int", "scif_clk";
			dmas = <&dmac1 0x37>, <&dmac1 0x36>;
			dma-names = "tx", "rx";
			power-domains = <&sysc R8A7798_PD_ALWAYS_ON>;
			status = "disabled";
		};

		scif0: serial@e6e60000 {
			compatible = "renesas,scif-r8a7798",
				     "renesas,rcar-gen3-scif", "renesas,scif";
			reg = <0 0xe6e60000 0 64>;
			interrupts = <GIC_SPI 152 IRQ_TYPE_LEVEL_HIGH>;		/* SPI152:SCIF.ch0 */
			clocks = <&cpg CPG_MOD 207>,
				 <&cpg CPG_CORE R8A7798_CLK_S2D1>,
				 <&scif_clk>;					/* RMSTPCR2/bit7:SCIF0 */
			/*clock-names = "fck", "sck", "brg_int", "scif_clk"; */
			clock-names = "fck";
			dmas = <&dmac1 0x51>, <&dmac1 0x50>;
			dma-names = "tx", "rx";
			power-domains = <&sysc R8A7798_PD_ALWAYS_ON>;
			status = "disabled";
		};

		scif1: serial@e6e68000 {
			compatible = "renesas,scif-r8a7798",
				     "renesas,rcar-gen3-scif", "renesas,scif";
			reg = <0 0xe6e68000 0 64>;
			interrupts = <GIC_SPI 153 IRQ_TYPE_LEVEL_HIGH>;		/* SPI153:SCIF.ch1 */
			clocks = <&cpg CPG_MOD 206>,
				 <&cpg CPG_CORE R8A7798_CLK_S2D1>,
				 <&scif_clk>;					/* RMSTPCR2/bit6:SCIF1 */
			clock-names = "fck", "brg_int", "scif_clk";
			dmas = <&dmac1 0x53>, <&dmac1 0x52>;
			dma-names = "tx", "rx";
			power-domains = <&sysc R8A7798_PD_ALWAYS_ON>;
			status = "disabled";
		};

		scif3: serial@e6c50000 {
			compatible = "renesas,scif-r8a7798",
				     "renesas,rcar-gen3-scif", "renesas,scif";
			reg = <0 0xe6c50000 0 64>;
			interrupts = <GIC_SPI 23 IRQ_TYPE_LEVEL_HIGH>;		/* SPI23:SCIF.ch3 */
			clocks = <&cpg CPG_MOD 204>,
				 <&cpg CPG_CORE R8A7798_CLK_S2D1>,
				 <&scif_clk>;					/* RMSTPCR2/bit4:SCIF3 */
			clock-names = "fck", "brg_int", "scif_clk";
			dmas = <&dmac1 0x57>, <&dmac1 0x56>;
			dma-names = "tx", "rx";
			power-domains = <&sysc R8A7798_PD_ALWAYS_ON>;
			status = "disabled";
		};

		scif4: serial@e6c40000 {
			compatible = "renesas,scif-r8a7798",
				     "renesas,rcar-gen3-scif", "renesas,scif";
			reg = <0 0xe6c40000 0 64>;
			interrupts = <GIC_SPI 16 IRQ_TYPE_LEVEL_HIGH>;		/* SPI16:SCIF.ch4 */
			clocks = <&cpg CPG_MOD 203>,
				 <&cpg CPG_CORE R8A7798_CLK_S2D1>,
				 <&scif_clk>;					/* RMSTPCR2/bit3:SCIF4 */
			clock-names = "fck", "brg_int", "scif_clk";
			dmas = <&dmac1 0x59>, <&dmac1 0x58>;
			dma-names = "tx", "rx";
			power-domains = <&sysc R8A7798_PD_ALWAYS_ON>;
			status = "disabled";
		};

		i2c0: i2c@e6500000 {
			#address-cells = <1>;
			#size-cells = <0>;
			compatible = "renesas,i2c-r8a7798";
			reg = <0 0xe6500000 0 0x40>;
			interrupts = <GIC_SPI 287 IRQ_TYPE_LEVEL_HIGH>;
			clocks = <&cpg CPG_MOD 931>;
			power-domains = <&sysc R8A7798_PD_ALWAYS_ON>;
			dmas = <&dmac1 0x91>, <&dmac1 0x90>;
			dma-names = "tx", "rx";
			i2c-scl-internal-delay-ns = <6>;
			status = "disabled";
		};

		i2c1: i2c@e6508000 {
			#address-cells = <1>;
			#size-cells = <0>;
			compatible = "renesas,i2c-r8a7798";
			reg = <0 0xe6508000 0 0x40>;
			interrupts = <GIC_SPI 288 IRQ_TYPE_LEVEL_HIGH>;
			clocks = <&cpg CPG_MOD 930>;
			power-domains = <&sysc R8A7798_PD_ALWAYS_ON>;
			dmas = <&dmac1 0x93>, <&dmac1 0x92>;
			dma-names = "tx", "rx";
			i2c-scl-internal-delay-ns = <6>;
			status = "disabled";
		};

		i2c2: i2c@e6510000 {
			#address-cells = <1>;
			#size-cells = <0>;
			compatible = "renesas,i2c-r8a7798";
			reg = <0 0xe6510000 0 0x40>;
			interrupts = <GIC_SPI 286 IRQ_TYPE_LEVEL_HIGH>;
			clocks = <&cpg CPG_MOD 929>;
			power-domains = <&sysc R8A7798_PD_ALWAYS_ON>;
			dmas = <&dmac1 0x95>, <&dmac1 0x94>;
			dma-names = "tx", "rx";
			i2c-scl-internal-delay-ns = <6>;
			status = "disabled";
		};

		i2c3: i2c@e66d0000 {
			#address-cells = <1>;
			#size-cells = <0>;
			compatible = "renesas,i2c-r8a7798";
			reg = <0 0xe66d0000 0 0x40>;
			interrupts = <GIC_SPI 290 IRQ_TYPE_LEVEL_HIGH>;
			clocks = <&cpg CPG_MOD 928>;
			power-domains = <&sysc R8A7798_PD_ALWAYS_ON>;
			dmas = <&dmac1 0x97>, <&dmac1 0x96>;
			dma-names = "tx", "rx";
			i2c-scl-internal-delay-ns = <6>;
			status = "disabled";
		};

		i2c4: i2c@e66d8000 {
			#address-cells = <1>;
			#size-cells = <0>;
			compatible = "renesas,i2c-r8a7798";
			reg = <0 0xe66d8000 0 0x40>;
			interrupts = <GIC_SPI 19 IRQ_TYPE_LEVEL_HIGH>;
			clocks = <&cpg CPG_MOD 927>;
			power-domains = <&sysc R8A7798_PD_ALWAYS_ON>;
			dmas = <&dmac1 0x99>, <&dmac1 0x98>;
			dma-names = "tx", "rx";
			i2c-scl-internal-delay-ns = <6>;
			status = "disabled";
		};

		i2c5: i2c@e66e0000 {
			#address-cells = <1>;
			#size-cells = <0>;
			compatible = "renesas,i2c-r8a7798";
			reg = <0 0xe66e0000 0 0x40>;
			interrupts = <GIC_SPI 20 IRQ_TYPE_LEVEL_HIGH>;
			clocks = <&cpg CPG_MOD 00>; /* FIXME missing entry in MSSR */
			power-domains = <&sysc R8A7798_PD_ALWAYS_ON>;
			dmas = <&dmac1 0x99>, <&dmac1 0x98>;
			dma-names = "tx", "rx";
			i2c-scl-internal-delay-ns = <6>;
			status = "disabled";
		};

		msiof0: spi@e6e90000 {
			#address-cells = <1>;
			#size-cells = <0>;
			compatible = "renesas,msiof-r8a7798";
			reg = <0 0xe6e90000 0 0x64>;
			interrupts = <GIC_SPI 156 IRQ_TYPE_LEVEL_HIGH>;
			clocks = <&cpg CPG_MOD 211>, <&msiof_ref_clk>;
			clock-names = "msiof_clk", "msiof_ref_clk";
			dmas = <&dmac1 0x41>, <&dmac1 0x40>;
			dma-names = "tx", "rx";
			power-domains = <&sysc R8A7798_PD_ALWAYS_ON>;
			status = "disabled";
		};

		msiof1: spi@e6ea0000 {
			#address-cells = <1>;
			#size-cells = <0>;
			compatible = "renesas,msiof-r8a7798";
			reg = <0 0xe6ea0000 0 0x0064>;
			interrupts = <GIC_SPI 157 IRQ_TYPE_LEVEL_HIGH>;
			clocks = <&cpg CPG_MOD 210>, <&msiof_ref_clk>;
			clock-names = "msiof_clk", "msiof_ref_clk";
			dmas = <&dmac1 0x43>, <&dmac1 0x42>;
			dma-names = "tx", "rx";
			power-domains = <&sysc R8A7798_PD_ALWAYS_ON>;
			status = "disabled";
		};

		msiof2: spi@e6c00000 {
			#address-cells = <1>;
			#size-cells = <0>;
			compatible = "renesas,msiof-r8a7798";
			reg = <0 0xe6c00000 0 0x0064>;
			interrupts = <GIC_SPI 158 IRQ_TYPE_LEVEL_HIGH>;
			clocks = <&cpg CPG_MOD 209>, <&msiof_ref_clk>;
			clock-names = "msiof_clk", "msiof_ref_clk";
			dmas = <&dmac1 0x45>, <&dmac1 0x44>;
			dma-names = "tx", "rx";
			power-domains = <&sysc R8A7798_PD_ALWAYS_ON>;
			status = "disabled";
		};

		msiof3: spi@e6c10000 {
			#address-cells = <1>;
			#size-cells = <0>;
			compatible = "renesas,msiof-r8a7798";
			reg = <0 0xe6c10000 0 0x0064>;
			interrupts = <GIC_SPI 159 IRQ_TYPE_LEVEL_HIGH>;
			clocks = <&cpg CPG_MOD 208>, <&msiof_ref_clk>;
			clock-names = "msiof_clk", "msiof_ref_clk";
			dmas = <&dmac1 0x47>, <&dmac1 0x46>;
			dma-names = "tx", "rx";
			power-domains = <&sysc R8A7798_PD_ALWAYS_ON>;
			status = "disabled";
		};


		pciec: pcie@fe000000 {
			compatible = "renesas,pcie-r8a7798",
				     "renesas,pcie-rcar-gen3";
			reg = <0 0xfe000000 0 0x80000>,
				<0 0xe65d0000 0 0x8000>;
			#address-cells = <3>;
			#size-cells = <2>;
			bus-range = <0x00 0xff>;
			device_type = "pci";
			ranges = <0x01000000 0 0x00000000 0 0xfe100000 0 0x00100000
				0x02000000 0 0xfe200000 0 0xfe200000 0 0x00200000
				0x02000000 0 0x30000000 0 0x30000000 0 0x08000000
				0x42000000 0 0x38000000 0 0x38000000 0 0x08000000>;
			dma-ranges = <0x42000000 0 0x40000000 0 0x40000000 0 0x80000000>;
			interrupts = <GIC_SPI 148 IRQ_TYPE_LEVEL_HIGH>,
				<GIC_SPI 149 IRQ_TYPE_LEVEL_HIGH>,
				<GIC_SPI 150 IRQ_TYPE_LEVEL_HIGH>;
			#interrupt-cells = <1>;
			interrupt-map-mask = <0 0 0 0>;
			interrupt-map = <0 0 0 0 &gic GIC_SPI 148 IRQ_TYPE_LEVEL_HIGH>;
			clocks = <&cpg CPG_MOD 319>, <&pcie_bus_clk>;
			clock-names = "pcie", "pcie_bus";
			power-domains = <&sysc R8A7798_PD_ALWAYS_ON>;
			status = "disabled";
		};

		vin0: video@e6ef0000 {
			compatible = "renesas,vin-r8a7798";
			reg = <0 0xe6ef0000 0 0x1000>;
			interrupts = <GIC_SPI 188 IRQ_TYPE_LEVEL_HIGH>;
			clocks = <&cpg CPG_MOD 811>;
			power-domains = <&sysc R8A7798_PD_ALWAYS_ON>;
			status = "disabled";
		};

		vin1: video@e6ef1000 {
			compatible = "renesas,vin-r8a7798";
			reg = <0 0xe6ef1000 0 0x1000>;
			interrupts = <GIC_SPI 189 IRQ_TYPE_LEVEL_HIGH>;
			clocks = <&cpg CPG_MOD 810>;
			power-domains = <&sysc R8A7798_PD_ALWAYS_ON>;
			status = "disabled";
		};

		vin2: video@e6ef2000 {
			compatible = "renesas,vin-r8a7798";
			reg = <0 0xe6ef2000 0 0x1000>;
			interrupts = <GIC_SPI 190 IRQ_TYPE_LEVEL_HIGH>;
			clocks = <&cpg CPG_MOD 809>;
			power-domains = <&sysc R8A7798_PD_ALWAYS_ON>;
			status = "disabled";
		};

		vin3: video@e6ef3000 {
			compatible = "renesas,vin-r8a7798";
			reg = <0 0xe6ef3000 0 0x1000>;
			interrupts = <GIC_SPI 191 IRQ_TYPE_LEVEL_HIGH>;
			clocks = <&cpg CPG_MOD 808>;
			power-domains = <&sysc R8A7798_PD_ALWAYS_ON>;
			status = "disabled";
		};

		vin4: video@e6ef4000 {
			compatible = "renesas,vin-r8a7798";
			reg = <0 0xe6ef4000 0 0x1000>;
			interrupts = <GIC_SPI 174 IRQ_TYPE_LEVEL_HIGH>;
			clocks = <&cpg CPG_MOD 807>;
			power-domains = <&sysc R8A7798_PD_ALWAYS_ON>;
			status = "disabled";
		};

		vin5: video@e6ef5000 {
			compatible = "renesas,vin-r8a7798";
			reg = <0 0xe6ef5000 0 0x1000>;
			interrupts = <GIC_SPI 175 IRQ_TYPE_LEVEL_HIGH>;
			clocks = <&cpg CPG_MOD 806>;
			power-domains = <&sysc R8A7798_PD_ALWAYS_ON>;
			status = "disabled";
		};

		vin6: video@e6ef6000 {
			compatible = "renesas,vin-r8a7798";
			reg = <0 0xe6ef6000 0 0x1000>;
			interrupts = <GIC_SPI 176 IRQ_TYPE_LEVEL_HIGH>;
			clocks = <&cpg CPG_MOD 805>;
			power-domains = <&sysc R8A7798_PD_ALWAYS_ON>;
			status = "disabled";
		};

		vin7: video@e6ef7000 {
			compatible = "renesas,vin-r8a7798";
			reg = <0 0xe6ef7000 0 0x1000>;
			interrupts = <GIC_SPI 171 IRQ_TYPE_LEVEL_HIGH>;
			clocks = <&cpg CPG_MOD 804>;
			power-domains = <&sysc R8A7798_PD_ALWAYS_ON>;
			status = "disabled";
		};

		vin8: video@e6ef8000 {
			compatible = "renesas,vin-r8a7798";
			reg = <0 0xe6ef8000 0 0x1000>;
			interrupts = <GIC_SPI 268 IRQ_TYPE_LEVEL_HIGH>;
			clocks = <&cpg CPG_MOD 628>;
			power-domains = <&sysc R8A7798_PD_ALWAYS_ON>;
			status = "disabled";
		};

		vin9: video@e6ef9000 {
			compatible = "renesas,vin-r8a7798";
			reg = <0 0xe6ef9000 0 0x1000>;
			interrupts = <GIC_SPI 269 IRQ_TYPE_LEVEL_HIGH>;
			clocks = <&cpg CPG_MOD 627>;
			power-domains = <&sysc R8A7798_PD_ALWAYS_ON>;
			status = "disabled";
		};

		vin10: video@e6efa000 {
			compatible = "renesas,vin-r8a7798";
			reg = <0 0xe6efa000 0 0x1000>;
			interrupts = <GIC_SPI 289 IRQ_TYPE_LEVEL_HIGH>;
			clocks = <&cpg CPG_MOD 625>;
			power-domains = <&sysc R8A7798_PD_ALWAYS_ON>;
			status = "disabled";
		};

		vin11: video@e6efb000 {
			compatible = "renesas,vin-r8a7798";
			reg = <0 0xe6efb000 0 0x1000>;
			interrupts = <GIC_SPI 296 IRQ_TYPE_LEVEL_HIGH>;
			clocks = <&cpg CPG_MOD 618>;
			power-domains = <&sysc R8A7798_PD_ALWAYS_ON>;
			status = "disabled";
		};

		vin12: video@e6efc000 {
			compatible = "renesas,vin-r8a7798";
			reg = <0 0xe6efc000 0 0x1000>;
			interrupts = <GIC_SPI 298 IRQ_TYPE_LEVEL_HIGH>;
			clocks = <&cpg CPG_MOD 612>;
			power-domains = <&sysc R8A7798_PD_ALWAYS_ON>;
			status = "disabled";
		};

		vin13: video@e6efd000 {
			compatible = "renesas,vin-r8a7798";
			reg = <0 0xe6efd000 0 0x1000>;
			interrupts = <GIC_SPI 299 IRQ_TYPE_LEVEL_HIGH>;
			clocks = <&cpg CPG_MOD 608>;
			power-domains = <&sysc R8A7798_PD_ALWAYS_ON>;
			status = "disabled";
		};

		vin14: video@e6efe000 {
			compatible = "renesas,vin-r8a7798";
			reg = <0 0xe6efe000 0 0x1000>;
			interrupts = <GIC_SPI 000 IRQ_TYPE_LEVEL_HIGH>; /* FIXME no info in datasheet */
			clocks = <&cpg CPG_MOD 605>;
			power-domains = <&sysc R8A7798_PD_ALWAYS_ON>;
			status = "disabled";
		};

		vin15: video@e6eff000 {
			compatible = "renesas,vin-r8a7798";
			reg = <0 0xe6eff000 0 0x1000>;
			interrupts = <GIC_SPI 000 IRQ_TYPE_LEVEL_HIGH>; /* FIXME no info in datasheet */
			clocks = <&cpg CPG_MOD 604>;
			power-domains = <&sysc R8A7798_PD_ALWAYS_ON>;
			status = "disabled";
		};

		sdhi2: sd@ee140000 {
			compatible = "renesas,sdhi-r8a7798";
			reg = <0 0xee140000 0 0x2000>;
			interrupts = <GIC_SPI 165 IRQ_TYPE_LEVEL_HIGH>;
			clocks = <&cpg CPG_MOD 314>;
			power-domains = <&sysc R8A7798_PD_ALWAYS_ON>;
			renesas,clk-rate = <200000000>;
			status = "disabled";
		};

		qos@e67e0000 {
			compatible = "renesas,qos";
		};

		vspd0: vsp@fea20000 {
			compatible = "renesas,vsp2";
			reg = <0 0xfea20000 0 0x4000>;

			interrupts = <GIC_SPI 169 IRQ_TYPE_LEVEL_HIGH>;
			clocks = <&cpg CPG_MOD 623>;
			power-domains = <&sysc R8A7798_PD_ALWAYS_ON>;

			renesas,fcp = <&fcpvd0>;
		};

		fcpvd0: fcp@fea27000 {
			compatible = "renesas,r8a7798-fcpv", "renesas,fcpv";
			reg = <0 0xfea27000 0 0x200>;
			clocks = <&cpg CPG_MOD 603>;
			power-domains = <&sysc R8A7798_PD_ALWAYS_ON>;
		};

		du: display@feb00000 {
			compatible = "renesas,du-r8a7798";
			reg = <0 0xfeb00000 0 0x80000>,
			      <0 0xfeb90000 0 0x14>;
			reg-names = "du", "lvds.0";
			interrupts = <GIC_SPI 256 IRQ_TYPE_LEVEL_HIGH>;
			clocks = <&cpg CPG_MOD 724>,
				 <&cpg CPG_MOD 727>,
				 <&dclkin_p0>;
			clock-names = "du.0", "lvds.0", "dclkin.0";
			status = "disabled";

			vsps = <&vspd0>;

			interlaced = <1>;

			ports {
				#address-cells = <1>;
				#size-cells = <0>;

				port@0 {
					reg = <0>;
					du_out_lvds0: endpoint {
					};
				};
			};
		};

		tsc1: thermal@0xe6198000 {
			compatible = "renesas,thermal-r8a7798";
			reg = <0 0xe6198000 0 0x5c>;
			interrupts = <GIC_SPI 67 IRQ_TYPE_LEVEL_HIGH>,
				     <GIC_SPI 68 IRQ_TYPE_LEVEL_HIGH>,
				     <GIC_SPI 69 IRQ_TYPE_LEVEL_HIGH>;
			clocks = <&cpg CPG_MOD 522>;
			power-domains = <&sysc R8A7798_PD_ALWAYS_ON>;
			#thermal-sensor-cells = <0>;
			status = "okay";
		};

		tsc2: thermal@0xe61a0000 {
			compatible = "renesas,thermal-r8a7798";
			reg = <0 0xe61a0000 0 0x5c>;
			interrupts = <GIC_SPI 67 IRQ_TYPE_LEVEL_HIGH>,
				     <GIC_SPI 68 IRQ_TYPE_LEVEL_HIGH>,
				     <GIC_SPI 69 IRQ_TYPE_LEVEL_HIGH>;
			clocks = <&cpg CPG_MOD 522>;
			power-domains = <&sysc R8A7798_PD_ALWAYS_ON>;
			#thermal-sensor-cells = <0>;
			status = "okay";
		};

		thermal-zones {
			emergency {
				polling-delay = <1000>;
				on-temperature = <110000>;
				off-temperature = <95000>;
				target_cpus = <&a53_1>,
					      <&a53_2>,
					      <&a53_3>;
				status = "disabled";
			};

			sensor_thermal1: sensor-thermal1 {
				polling-delay-passive = <250>;
				polling-delay = <0>;
				sustainable-power = <0>; /* TBD; HWM 87.4 */

				thermal-sensors = <&tsc1>;

				trips {
					sensor1_crit: sensor1-crit {
						temperature = <120000>;
						hysteresis = <2000>;
						type = "critical";
					};
				};
			};

			sensor_thermal2: sensor-thermal2 {
				polling-delay-passive = <250>;
				polling-delay = <0>;
				sustainable-power = <0>; /* TBD; HWM 87.4 */

				thermal-sensors = <&tsc2>;

				trips {
					sensor2_crit: sensor2-crit {
						temperature = <120000>;
						hysteresis = <2000>;
						type = "critical";
					};
				};
			};
		};

		mfis: mfis@e6260000 {
			compatible = "renesas,mfis-r8a7798", "renesas,mfis";
			reg = <0 0xe6260000 0 0x0200>;
			clocks = <&cpg CPG_MOD 213>;
			clock-names = "mfis";
			interrupts = <GIC_SPI 180 IRQ_TYPE_LEVEL_HIGH>;
			interrupt-names = "eicr0";
			status = "okay";
		};

		mfis_lock: mfis-lock@e62600c0 {
			compatible =    "renesas,mfis-lock-r8a7798",
					"renesas,mfis-lock";
			reg = <0 0xe62600c0 0 0x0020>;
			status = "okay";
		};

		imp_distributer: impdes0 {
			compatible = "renesas,impx5+-distributer";
			reg = <0 0xffa00000 0 0x10000>;
			interrupts = <GIC_SPI 281 IRQ_TYPE_LEVEL_HIGH>;
			clocks = <&cpg CPG_MOD 830>;
			power-domains = <&sysc R8A7798_PD_A3IR>;
			interrupt-controller;
			#interrupt-cells = <1>;
		};

		imp0 {
			compatible = "renesas,impx4-legacy";
			reg = <0 0xff900000 0 0x20000>;
			interrupt-parent = <&imp_distributer>;
			interrupts = <0>;
			clocks = <&cpg CPG_MOD 827>;
			power-domains = <&sysc R8A7798_PD_A2IR0>;
		};

		imp1 {
			compatible = "renesas,impx4-legacy";
			reg = <0 0xff920000 0 0x20000>;
			interrupt-parent = <&imp_distributer>;
			interrupts = <1>;
			clocks = <&cpg CPG_MOD 826>;
			power-domains = <&sysc R8A7798_PD_A2IR1>;
		};

		imp2 {
			compatible = "renesas,impx4-legacy";
			reg = <0 0xff940000 0 0x20000>;
			interrupt-parent = <&imp_distributer>;
			interrupts = <2>;
			clocks = <&cpg CPG_MOD 825>;
			power-domains = <&sysc R8A7798_PD_A2IR2>;
		};

		imp3 {
			compatible = "renesas,impx4-legacy";
			reg = <0 0xff960000 0 0x20000>;
			interrupt-parent = <&imp_distributer>;
			interrupts = <3>;
			clocks = <&cpg CPG_MOD 824>;
			power-domains = <&sysc R8A7798_PD_A2IR3>;
		};

		imp4 {
			compatible = "renesas,impx4-legacy";
			reg = <0 0xffa80000 0 0x20000>;
			interrupt-parent = <&imp_distributer>;
			interrupts = <4>;
			clocks = <&cpg CPG_MOD 521>;
			power-domains = <&sysc R8A7798_PD_A2IR4>;
		};

		impslc0 {
			compatible = "renesas,impx4-legacy";
			reg = <0 0xff9c0000 0 0x10000>;
			interrupt-parent = <&imp_distributer>;
			interrupts = <5>;
			clocks = <&cpg CPG_MOD 500>;
			power-domains = <&sysc R8A7798_PD_A2IR5>;
		};

		impsc0 {
			compatible = "renesas,impx4-shader";
			reg = <0 0xff980000 0 0x10000>;
			interrupt-parent = <&imp_distributer>;
			interrupts = <6>;
			clocks = <&cpg CPG_MOD 829>;
			power-domains = <&sysc R8A7798_PD_A2SC0>;
		};

		impsc1 {
			compatible = "renesas,impx4-shader";
			reg = <0 0xff990000 0 0x10000>;
			interrupt-parent = <&imp_distributer>;
			interrupts = <7>;
			clocks = <&cpg CPG_MOD 828>;
			power-domains = <&sysc R8A7798_PD_A2SC1>;
		};

		impsc2 {
			compatible = "renesas,impx4-shader";
			reg = <0 0xff9a0000 0 0x10000>;
			interrupt-parent = <&imp_distributer>;
			interrupts = <8>;
			clocks = <&cpg CPG_MOD 531>;
			power-domains = <&sysc R8A7798_PD_A2SC2>;
		};

		impsc3 {
			compatible = "renesas,impx4-shader";
			reg = <0 0xff9b0000 0 0x10000>;
			interrupt-parent = <&imp_distributer>;
			interrupts = <9>;
			clocks = <&cpg CPG_MOD 529>;
			power-domains = <&sysc R8A7798_PD_A2SC3>;
		};

		impsc4 {
			compatible = "renesas,impx4-shader";
			reg = <0 0xffa40000 0 0x10000>;
			interrupt-parent = <&imp_distributer>;
			interrupts = <10>;
			clocks = <&cpg CPG_MOD 528>;
			power-domains = <&sysc R8A7798_PD_A2SC4>;
		};

		impdm0 {
			compatible = "renesas,impx5-dmac";
			reg = <0 0xffa10000 0 0x1000>;
			interrupt-parent = <&imp_distributer>;
			interrupts = <11>;
			clocks = <&cpg CPG_MOD 527>;
			power-domains = <&sysc R8A7798_PD_A2PD0>;
		};

		impdm1 {
			compatible = "renesas,impx5-dmac";
			reg = <0 0xffa11000 0 0x1000>;
			interrupt-parent = <&imp_distributer>;
			interrupts = <12>;
			clocks = <&cpg CPG_MOD 527>;
			power-domains = <&sysc R8A7798_PD_A2PD0>;
		};

		impdm2 {
			compatible = "renesas,impx5-dmac";
			reg = <0 0xffa14000 0 0x1000>;
			interrupt-parent = <&imp_distributer>;
			interrupts = <13>;
			clocks = <&cpg CPG_MOD 526>;
			power-domains = <&sysc R8A7798_PD_A2PD1>;
		};

		impdm3 {
			compatible = "renesas,impx5-dmac";
			reg = <0 0xffa15000 0 0x1000>;
			interrupt-parent = <&imp_distributer>;
			interrupts = <14>;
			clocks = <&cpg CPG_MOD 526>;
			power-domains = <&sysc R8A7798_PD_A2PD1>;
		};

		imppsc0 {
			compatible = "renesas,impx5+-psc";
			reg = <0 0xffa20000 0 0x4000>;
			interrupt-parent = <&imp_distributer>;
			interrupts = <15>;
			clocks = <&cpg CPG_MOD 525>;
			power-domains = <&sysc R8A7798_PD_A2PD0>;
		};

		imppsc1 {
			compatible = "renesas,impx5+-psc";
			reg = <0 0xffa24000 0 0x4000>;
			interrupt-parent = <&imp_distributer>;
			interrupts = <16>;
			clocks = <&cpg CPG_MOD 524>;
			power-domains = <&sysc R8A7798_PD_A2PD1>;
		};

		impcnn0 {
			compatible = "renesas,impx5+-cnn";
			reg = <0 0xff9e0000 0 0x10000>;
			interrupt-parent = <&imp_distributer>;
			interrupts = <17>;
			clocks = <&cpg CPG_MOD 831>;
			power-domains = <&sysc R8A7798_PD_A2CN>;
		};

		impc0 {
			compatible = "renesas,impx4-memory";
			reg = <0 0xed000000 0 0x200000>;
			clocks = <&cpg CPG_MOD 830>;
			power-domains = <&sysc R8A7798_PD_A3IR>;
		};

		imrlx4_ch0: imr-lx4@fe860000 {
			compatible = "renesas,imr-lx4";
			reg = <0 0xfe860000 0 0x2000>;
			interrupts = <GIC_SPI 192 IRQ_TYPE_LEVEL_HIGH>;
			clocks = <&cpg CPG_MOD 823>;
			power-domains = <&sysc R8A7798_PD_ALWAYS_ON>;
		};

		imrlx4_ch1: imr-lx4@fe870000 {
			compatible = "renesas,imr-lx4";
			reg = <0 0xfe870000 0 0x2000>;
			interrupts = <GIC_SPI 193 IRQ_TYPE_LEVEL_HIGH>;
			clocks = <&cpg CPG_MOD 822>;
			power-domains = <&sysc R8A7798_PD_ALWAYS_ON>;
		};

		imrlx4_ch2: imr-lx4@fe880000 {
			compatible = "renesas,imr-lx4";
			reg = <0 0xfe880000 0 0x2000>;
			interrupts = <GIC_SPI 194 IRQ_TYPE_LEVEL_HIGH>;
			clocks = <&cpg CPG_MOD 821>;
			power-domains = <&sysc R8A7798_PD_ALWAYS_ON>;
		};

		imrlx4_ch3: imr-lx4@fe890000 {
			compatible = "renesas,imr-lx4";
			reg = <0 0xfe890000 0 0x2000>;
			interrupts = <GIC_SPI 195 IRQ_TYPE_LEVEL_HIGH>;
			clocks = <&cpg CPG_MOD 820>;
			power-domains = <&sysc R8A7798_PD_ALWAYS_ON>;
		};

		imrlx4_ch4: imr-lx4@fe8a0000 {
			compatible = "renesas,imr-lx4";
			reg = <0 0xfe8a0000 0 0x2000>;
			interrupts = <GIC_SPI 254 IRQ_TYPE_LEVEL_HIGH>;
			clocks = <&cpg CPG_MOD 707>;
			power-domains = <&sysc R8A7798_PD_ALWAYS_ON>;
			rse;
		};

		imrlx4_ch5: imr-lx4@fe8b0000 {
			compatible = "renesas,imr-lx4";
			reg = <0 0xfe8b0000 0 0x2000>;
			interrupts = <GIC_SPI 255 IRQ_TYPE_LEVEL_HIGH>;
			clocks = <&cpg CPG_MOD 706>;
			power-domains = <&sysc R8A7798_PD_ALWAYS_ON>;
			rse;
		};

		disp {
			compatible = "generic-uio";
			reg = <0 0xe7a00000 0 0x10000>;
			clocks = <&cpg CPG_MOD 101>;
			power-domains = <&sysc R8A7798_PD_A3VIP>;
		};

		umf {
			compatible = "generic-uio";
			reg = <0 0xe7a10000 0 0x10000>;
			clocks = <&cpg CPG_MOD 102>;
			power-domains = <&sysc R8A7798_PD_A3VIP1>;
		};

		smd_ps {
			compatible = "generic-uio";
			reg = <0 0xe7a20000 0 0x10000>;
			clocks = <&cpg CPG_MOD 1102>;
			power-domains = <&sysc R8A7798_PD_A3VIP1>;
		};

		smd_est {
			compatible = "generic-uio";
			reg = <0 0xe7a30000 0 0x10000>;
			clocks = <&cpg CPG_MOD 1101>;
			power-domains = <&sysc R8A7798_PD_A3VIP1>;
		};

		smd_post {
			compatible = "generic-uio";
			reg = <0 0xe7a40000 0 0x10000>;
			clocks = <&cpg CPG_MOD 1100>;
			power-domains = <&sysc R8A7798_PD_A3VIP1>;
		};

		cle0 {
			compatible = "generic-uio";
			reg = <0 0xe7a50000 0 0x10000>;
			clocks = <&cpg CPG_MOD 1004>;
			power-domains = <&sysc R8A7798_PD_A3VIP2>;
		};

		cle1 {
			compatible = "generic-uio";
			reg = <0 0xe7a60000 0 0x10000>;
			clocks = <&cpg CPG_MOD 1003>;
			power-domains = <&sysc R8A7798_PD_A3VIP2>;
		};

		cle2 {
			compatible = "generic-uio";
			reg = <0 0xe7a70000 0 0x10000>;
			clocks = <&cpg CPG_MOD 1002>;
			power-domains = <&sysc R8A7798_PD_A3VIP2>;
		};

		cle3 {
			compatible = "generic-uio";
			reg = <0 0xe7a80000 0 0x10000>;
			clocks = <&cpg CPG_MOD 1001>;
			power-domains = <&sysc R8A7798_PD_A3VIP2>;
		};

		cle4 {
			compatible = "generic-uio";
			reg = <0 0xe7a90000 0 0x10000>;
			clocks = <&cpg CPG_MOD 1000>;
			power-domains = <&sysc R8A7798_PD_A3VIP2>;
		};
	};
};
